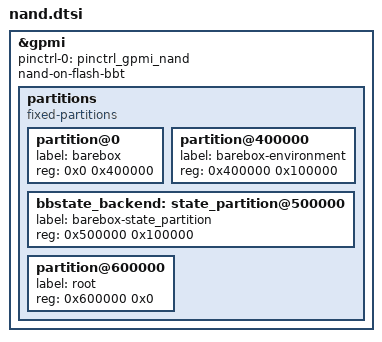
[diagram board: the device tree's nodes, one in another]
&gpmi {
	pinctrl-names = "default";
	pinctrl-0 = <&pinctrl_gpmi_nand>;
	nand-on-flash-bbt;
	status = "okay";
	#address-cells = <1>;
	#size-cells = <1>;

	/delete-node/ partitions;
	partitions {
		compatible = "fixed-partitions";
		#address-cells = <1>;
		#size-cells = <1>;

		partition@0 {
			label = "barebox";
			reg = <0x0 0x400000>;
		};

		partition@400000 {
			label = "barebox-environment";
			reg = <0x400000 0x100000>;
		};

		bbstate_backend: state_partition@500000 {
			label = "barebox-state_partition";
			reg = <0x500000 0x100000>;
		};

		partition@600000 {
			label = "root";
			reg = <0x600000 0x0>;
		};
	};
};
